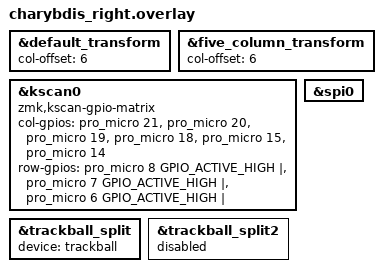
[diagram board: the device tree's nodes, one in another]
#include "charybdis.dtsi"
#include "charybdis_3610.dtsi"
#include "split_input_common.dtsi"

&default_transform {
	col-offset = <6>;
};

&five_column_transform {
	col-offset = <6>;
};

&kscan0 {
	compatible = "zmk,kscan-gpio-matrix";
	
	col-gpios
		= <&pro_micro 21 (GPIO_ACTIVE_HIGH)>
		, <&pro_micro 20 (GPIO_ACTIVE_HIGH)>
		, <&pro_micro 19 (GPIO_ACTIVE_HIGH)>
		, <&pro_micro 18 (GPIO_ACTIVE_HIGH)>
		, <&pro_micro 15 (GPIO_ACTIVE_HIGH)>
		, <&pro_micro 14 (GPIO_ACTIVE_HIGH)>
		;

	row-gpios
		= <&pro_micro 8 GPIO_ACTIVE_HIGH | GPIO_PULL_DOWN>
		, <&pro_micro 7 GPIO_ACTIVE_HIGH | GPIO_PULL_DOWN>
		, <&pro_micro 6 GPIO_ACTIVE_HIGH | GPIO_PULL_DOWN>
		;
};
&spi0 {
    status = "okay";
};
&trackball_split { 
	device = <&trackball>; 
	};
&trackball_split2 { 
	status = "disabled"; 
};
